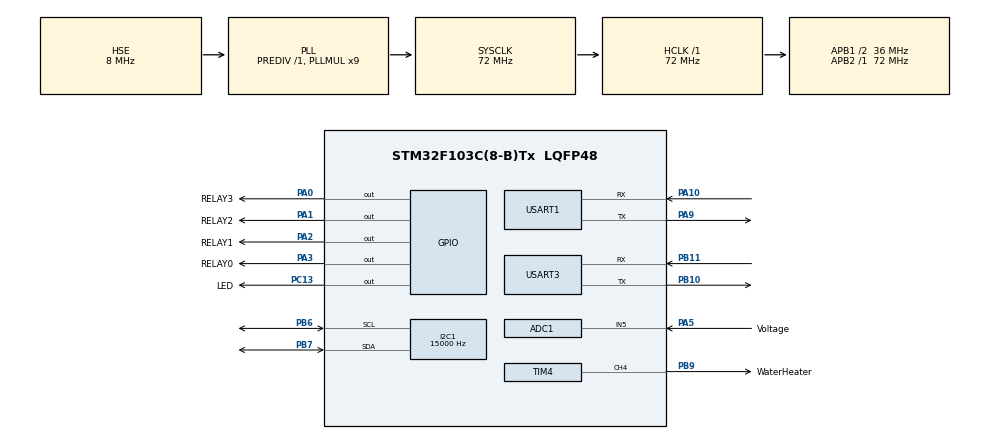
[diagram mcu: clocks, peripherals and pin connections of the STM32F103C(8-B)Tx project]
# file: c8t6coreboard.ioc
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ADC1.Channel-1\#ChannelRegularConversion=ADC_CHANNEL_5
ADC1.NbrOfConversionFlag=1
ADC1.Rank-1\#ChannelRegularConversion=1
ADC1.SamplingTime-1\#ChannelRegularConversion=ADC_SAMPLETIME_1CYCLE_5
ADC1.master=1
I2C1.ClockSpeed=15000
I2C1.I2C_Mode=I2C_Standard
Mcu.Family=STM32F1
Mcu.Name=STM32F103C(8-B)Tx
Mcu.Package=LQFP48
NVIC.PriorityGroup=NVIC_PRIORITYGROUP_4
NVIC.TIM1_UP_IRQn=true\:1\:0\:true\:false\:true\:true\:true\:true
NVIC.USART1_IRQn=true\:0\:0\:false\:false\:true\:true\:true\:true
NVIC.USART3_IRQn=true\:0\:0\:false\:false\:true\:true\:true\:true
PA0-WKUP.GPIO_Label=RELAY3
PA0-WKUP.Signal=GPIO_Output
PA1.GPIO_Label=RELAY2
PA1.Signal=GPIO_Output
PA10.Mode=Asynchronous
PA10.Signal=USART1_RX
PA13.Mode=Serial_Wire
PA13.Signal=SYS_JTMS-SWDIO
PA14.Mode=Serial_Wire
PA14.Signal=SYS_JTCK-SWCLK
PA2.GPIO_Label=RELAY1
PA2.Signal=GPIO_Output
PA3.GPIO_Label=RELAY0
PA3.Signal=GPIO_Output
PA5.GPIO_Label=Voltage
PA5.Signal=ADCx_IN5
PA9.Mode=Asynchronous
PA9.Signal=USART1_TX
PB10.Mode=Asynchronous
PB10.Signal=USART3_TX
PB11.Mode=Asynchronous
PB11.Signal=USART3_RX
PB6.Mode=I2C
PB6.Signal=I2C1_SCL
PB7.Mode=I2C
PB7.Signal=I2C1_SDA
PB9.GPIO_Label=WaterHeater
PB9.GPIO_Speed=GPIO_SPEED_FREQ_LOW
PB9.Signal=S_TIM4_CH4
PC13-TAMPER-RTC.GPIO_Label=LED
PC13-TAMPER-RTC.Signal=GPIO_Output
PC14-OSC32_IN.Mode=LSE-External-Oscillator
PC14-OSC32_IN.Signal=RCC_OSC32_IN
PC15-OSC32_OUT.Mode=LSE-External-Oscillator
PC15-OSC32_OUT.Signal=RCC_OSC32_OUT
PD0-OSC_IN.Mode=HSE-External-Oscillator
PD0-OSC_IN.Signal=RCC_OSC_IN
PD1-OSC_OUT.Mode=HSE-External-Oscillator
PD1-OSC_OUT.Signal=RCC_OSC_OUT
ProjectManager.HeapSize=0x200
ProjectManager.StackSize=0x400
ProjectManager.TargetToolchain=CMake
RCC.ADCPresc=RCC_ADCPCLK2_DIV6
RCC.AHBFreq_Value=72000000
RCC.APB1CLKDivider=RCC_HCLK_DIV2
RCC.APB1Freq_Value=36000000
RCC.APB1TimFreq_Value=72000000
RCC.APB2Freq_Value=72000000
RCC.APB2TimFreq_Value=72000000
RCC.HCLKFreq_Value=72000000
RCC.PLLMUL=RCC_PLL_MUL9
RCC.PLLSourceVirtual=RCC_PLLSOURCE_HSE
RCC.SYSCLKFreq_VALUE=72000000
RCC.SYSCLKSource=RCC_SYSCLKSOURCE_PLLCLK
RCC.USBFreq_Value=48000000
RCC.USBPrescaler=RCC_USBCLKSOURCE_PLL_DIV1_5
SH.ADCx_IN5.0=ADC1_IN5,IN5
SH.S_TIM4_CH4.0=TIM4_CH4,PWM Generation4 CH4
TIM1.Period=4000-1
TIM1.Prescaler=36000-1
TIM4.Channel-PWM\ Generation4\ CH4=TIM_CHANNEL_4
TIM4.Period=10000-1
TIM4.Prescaler=72-1
USART1.VirtualMode=VM_ASYNC
USART3.VirtualMode=VM_ASYNC
VP_TIM1_VS_ClockSourceINT.Mode=Internal
VP_TIM4_VS_ClockSourceINT.Mode=Internal
board=custom

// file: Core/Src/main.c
/* USER CODE BEGIN Header */
/**
  ******************************************************************************
  * @file           : main.c
  * @brief          : Main program body
  ******************************************************************************
  * @attention
  *
  * Copyright (c) 2025 STMicroelectronics.
  * All rights reserved.
  *
  * This software is licensed under terms that can be found in the LICENSE file
  * in the root directory of this software component.
  * If no LICENSE file comes with this software, it is provided AS-IS.
  *
  ******************************************************************************
  */
/* USER CODE END Header */
#include "main.h"
#include "adc.h"
#include "i2c.h"
#include "tim.h"
#include "usart.h"
#include "gpio.h"

/* USER CODE BEGIN Includes */
#include "arduino.h"
/* USER CODE END Includes */

void SystemClock_Config(void);

int main(void)
{

  /* MCU Configuration--------------------------------------------------------*/

  /* Reset of all peripherals, Initializes the Flash interface and the Systick. */
  HAL_Init();

  /* Configure the system clock */
  SystemClock_Config();

  /* Initialize all configured peripherals */
  MX_GPIO_Init();
  MX_I2C1_Init();
  MX_USART3_UART_Init();
  MX_USART1_UART_Init();
  MX_TIM1_Init();
  MX_ADC1_Init();
  MX_TIM4_Init();
  /* USER CODE BEGIN 2 */
  HAL_ADCEx_Calibration_Start(&hadc1);
  setup();
  /* USER CODE END 2 */

  /* Infinite loop */
  while (1)
  {

    /* USER CODE BEGIN 3 */
    loop();
  }
  /* USER CODE END 3 */
}

void SystemClock_Config(void)
{
  RCC_OscInitTypeDef RCC_OscInitStruct = {0};
  RCC_ClkInitTypeDef RCC_ClkInitStruct = {0};
  RCC_PeriphCLKInitTypeDef PeriphClkInit = {0};

  /** Initializes the RCC Oscillators according to the specified parameters
  * in the RCC_OscInitTypeDef structure.
  */
  RCC_OscInitStruct.OscillatorType = RCC_OSCILLATORTYPE_HSE;
  RCC_OscInitStruct.HSEState = RCC_HSE_ON;
  RCC_OscInitStruct.HSEPredivValue = RCC_HSE_PREDIV_DIV1;
  RCC_OscInitStruct.HSIState = RCC_HSI_ON;
  RCC_OscInitStruct.PLL.PLLState = RCC_PLL_ON;
  RCC_OscInitStruct.PLL.PLLSource = RCC_PLLSOURCE_HSE;
  RCC_OscInitStruct.PLL.PLLMUL = RCC_PLL_MUL9;
  if (HAL_RCC_OscConfig(&RCC_OscInitStruct) != HAL_OK)
  {
    Error_Handler();
  }

  /** Initializes the CPU, AHB and APB buses clocks
  */
  RCC_ClkInitStruct.ClockType = RCC_CLOCKTYPE_HCLK|RCC_CLOCKTYPE_SYSCLK
                              |RCC_CLOCKTYPE_PCLK1|RCC_CLOCKTYPE_PCLK2;
  RCC_ClkInitStruct.SYSCLKSource = RCC_SYSCLKSOURCE_PLLCLK;
  RCC_ClkInitStruct.AHBCLKDivider = RCC_SYSCLK_DIV1;
  RCC_ClkInitStruct.APB1CLKDivider = RCC_HCLK_DIV2;
  RCC_ClkInitStruct.APB2CLKDivider = RCC_HCLK_DIV1;

  if (HAL_RCC_ClockConfig(&RCC_ClkInitStruct, FLASH_LATENCY_2) != HAL_OK)
  {
    Error_Handler();
  }
  PeriphClkInit.PeriphClockSelection = RCC_PERIPHCLK_ADC;
  PeriphClkInit.AdcClockSelection = RCC_ADCPCLK2_DIV6;
  if (HAL_RCCEx_PeriphCLKConfig(&PeriphClkInit) != HAL_OK)
  {
    Error_Handler();
  }
}

void Error_Handler(void)
{
  __disable_irq();
  while (1)
  {
  }
}
